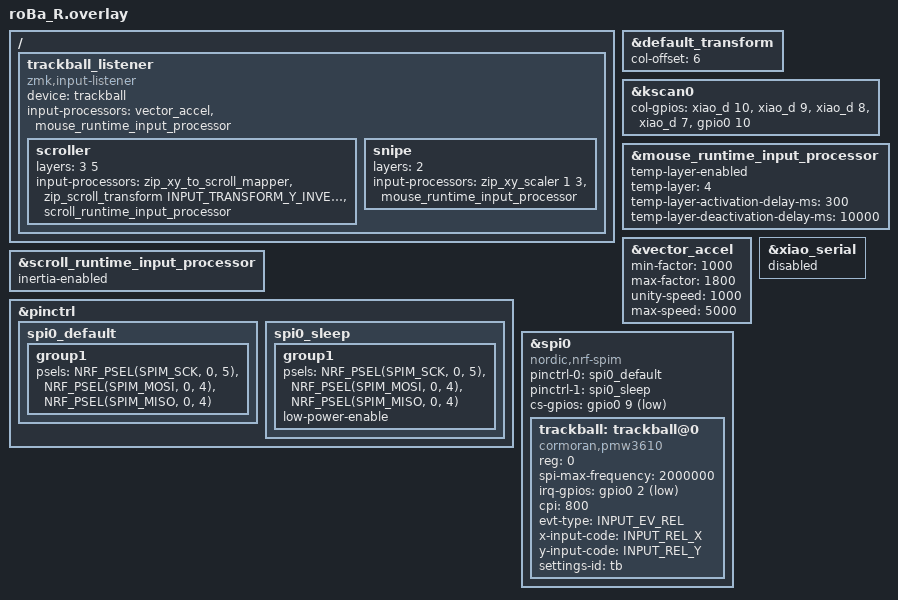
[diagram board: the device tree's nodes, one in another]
#include "roBa.dtsi"
#include <input/processors.dtsi>
#include <input/processors/runtime-input-processor.dtsi>
#include <zmk-input-vector-acceleration/input_processor_vector_accel.dtsi>
#include <dt-bindings/zmk/input_transform.h>

&default_transform {
    col-offset = <6>;
};

&kscan0 {
        col-gpios
            = <&xiao_d 10 GPIO_ACTIVE_HIGH>
            , <&xiao_d 9 GPIO_ACTIVE_HIGH>
            , <&xiao_d 8 GPIO_ACTIVE_HIGH>
            , <&xiao_d 7 GPIO_ACTIVE_HIGH>
            , <&gpio0 10 GPIO_ACTIVE_HIGH>
            ;
};

// オートマウス: トラックボールを動かすとレイヤー 4（MOUSE）に入り、ボールを止めて 10 秒たつか、
// MOUSE レイヤーで &trans のキーを押すまで続く。
// ここは初期値で、DYA Studio で変更して保存した値があればそちらが優先される。
&mouse_runtime_input_processor {
    temp-layer-enabled;
    temp-layer = <4>;
    // キーコードを送るキーを押してから 300 ms は、ボールが動いてもレイヤーを有効にしない（入力中に手が触れて
    // 入るのを減らす）。&lt の長押しとマウスボタンは数えない
    temp-layer-activation-delay-ms = <300>;
    // カーソルを最後に動かしてから 10 秒で解除する（クリックや LANG1 のスクロールでは延びない）。
    // MOUSE レイヤーで割り当てのないキーを押せば、その場で解除される。
    // DYA Studio のスライダーは 2000 ms までなので、この長さはここでしか指定できない
    temp-layer-deactivation-delay-ms = <10000>;
};

// ポインタ加速の初期値（DYA Studio で保存した値があればそちらが優先される）。
// 速さは 1 秒あたりのカウント数（CPI 800 なので 1000 カウント/秒 ≒ 指の速さ 32 mm/秒）。
// 1000 カウント/秒までは倍率 1.0 で、ゆっくり動かしたときは IST PLUS と同じ。それより速いと二次曲線で
// 大きくなり、5000 カウント/秒以上で最大の 1.8 倍（2000 で 1.05、3000 で 1.2、4000 で 1.45）。
// 無効にするときは max-factor を 1000 にする（全速度で 1.0 になる）
&vector_accel {
    min-factor = <1000>;
    max-factor = <1800>;
    unity-speed = <1000>;
    max-speed = <5000>;
};

// スクロールの慣性（弾くと惰性で流れる）を既定で有効にする。DYA Studio で保存した値があればそちらが優先される。
// 公開版の DYA Studio には慣性の設定画面がないので、調整は開発版（dya-studio-dev）で行う
&scroll_runtime_input_processor {
    inertia-enabled;
};

/ {
    trackball_listener {
        status = "okay";
        compatible = "zmk,input-listener";
        device = <&trackball>;
        // 加速は実行時プロセッサ（RIP）より前に置く。RIP の倍率に関係なくセンサーの生のカウントで速さを
        // 判定するため。倍率が 1.0 未満にならないので、オートマウスの判定（動きがあるか）は変わらない
        input-processors = <&vector_accel>, <&mouse_runtime_input_processor>;

        // 子ノードは上から順に調べられ、最初に当てはまったものだけが使われる
        scroller {
            // LANG1 を長押ししている間（ARROW レイヤー 3）、ボールの動きをスクロールにする。
            // SCROLL レイヤー（5）は入るキーがないが、番号を保つために残している
            layers = <3 5>;
            // Y 反転は入力プロセッサ（RIP）より前に置く。慣性の出力は RIP から直接ホストへ送られて
            // 後段のプロセッサを通らないため、後ろで反転すると慣性だけ逆向きに流れる
            input-processors =
                <&zip_xy_to_scroll_mapper>,
                <&zip_scroll_transform INPUT_TRANSFORM_Y_INVERT>,
                <&scroll_runtime_input_processor>;
        };

        // 低速モード: SPACE を長押ししている間（NUM レイヤー 2）、カーソルを 1/3 の速さにする。
        // 端数は持ち越されるので、ゆっくり動かしても動きは抜けない
        snipe {
            layers = <2>;
            input-processors = <&zip_xy_scaler 1 3>, <&mouse_runtime_input_processor>;
        };
    };
};

&pinctrl {
    spi0_default: spi0_default {
        group1 {
            psels = <NRF_PSEL(SPIM_SCK, 0, 5)>,
                <NRF_PSEL(SPIM_MOSI, 0, 4)>,
                <NRF_PSEL(SPIM_MISO, 0, 4)>;
        };
    };

    spi0_sleep: spi0_sleep {
        group1 {
            psels = <NRF_PSEL(SPIM_SCK, 0, 5)>,
                <NRF_PSEL(SPIM_MOSI, 0, 4)>,
                <NRF_PSEL(SPIM_MISO, 0, 4)>;
            low-power-enable;
        };
    };
};

&xiao_serial { status = "disabled"; };

&spi0 {
    status = "okay";
    compatible = "nordic,nrf-spim";
    pinctrl-0 = <&spi0_default>;
    pinctrl-1 = <&spi0_sleep>;
    pinctrl-names = "default", "sleep";
    cs-gpios = <&gpio0 9 GPIO_ACTIVE_LOW>;

    trackball: trackball@0 {
        status = "okay";
        compatible = "cormoran,pmw3610";
        reg = <0>;
        spi-max-frequency = <2000000>;
        irq-gpios = <&gpio0 2 (GPIO_ACTIVE_LOW | GPIO_PULL_UP)>;
        // 普段使っているエレコム IST PLUS（800 DPI に設定）と、指を同じだけ動かしたときの
        // カーソルの移動量をそろえる。センサーが受け付けるのは 200 刻み（200〜3200）。
        // DYA Studio で保存した値があれば、そちらが優先される
        cpi = <800>;
        evt-type = <INPUT_EV_REL>;
        x-input-code = <INPUT_REL_X>;
        y-input-code = <INPUT_REL_Y>;
        // 実行時設定のキー "<param>@tb" に使う ID（保存名の長さ制限があるので短くする）
        settings-id = "tb";
    };
};
